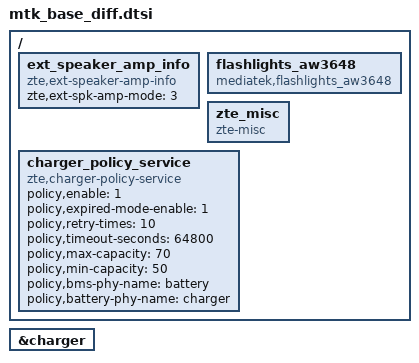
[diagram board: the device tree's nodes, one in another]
/*
 * when you want to delete some nodes or property, modify this dtsi.
 * some diff between mtk and zte pluto.
 */

/{
	ext_speaker_amp_info {
		status="okay";
		compatible = "zte,ext-speaker-amp-info";
		zte,ext-spk-amp-mode = <3>;
	};
		/*add for Z3351S flash chip node*/
	flashlights_aw3648: flashlights_aw3648 {
		compatible = "mediatek,flashlights_aw3648";
	};

	zte_misc: zte_misc {
		status="okay";
		compatible = "zte-misc";
	};

	charger_policy_service {
		compatible = "zte,charger-policy-service";
		status="okay";
		policy,enable = <1>;
		policy,expired-mode-enable = <1>;
		policy,retry-times = <10>;
		policy,timeout-seconds = <64800>;/* 18 hours */
		policy,max-capacity = <70>;
		policy,min-capacity = <50>;
		policy,bms-phy-name = "battery";
		policy,battery-phy-name = "charger";
	};

};

&charger {
	/delete-property/ enable_pe_plus;
	/delete-property/ enable_pe_2;
	/delete-property/ enable_pe_3;
	/delete-property/ enable_sw_safety_timer;
};
